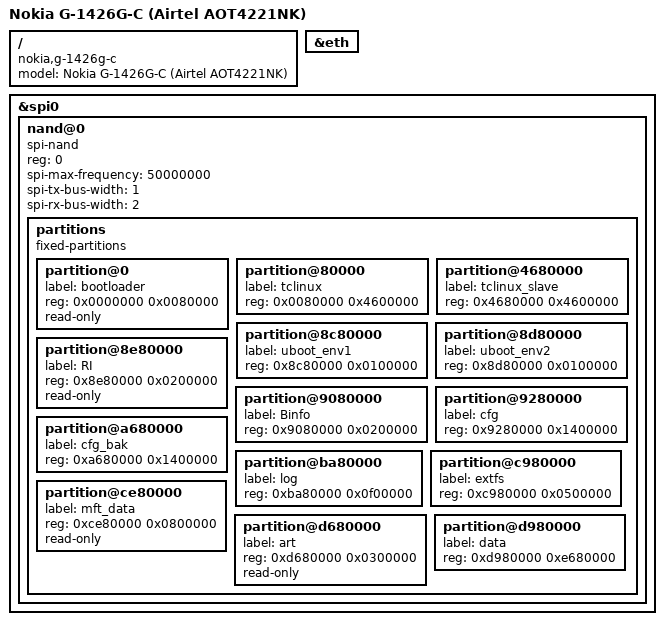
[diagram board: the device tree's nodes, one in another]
// SPDX-License-Identifier: (GPL-2.0-only OR BSD-2-Clause)
/dts-v1/;

#include "an7552.dtsi"

/ {
	model = "Nokia G-1426G-C (Airtel AOT4221NK)";
	compatible = "nokia,g-1426g-c", "airoha,an7552";
};

&eth {
	status = "okay";
};

&spi0 {
	status = "okay";

	nand@0 {
		compatible = "spi-nand";
		reg = <0>;
		spi-max-frequency = <50000000>;
		spi-tx-bus-width = <1>;
		spi-rx-bus-width = <2>;

		partitions {
			compatible = "fixed-partitions";
			#address-cells = <1>;
			#size-cells = <1>;

			partition@0 {
				label = "bootloader";
				reg = <0x0000000 0x0080000>;
				read-only;
			};

			partition@80000 {
				label = "tclinux";
				reg = <0x0080000 0x4600000>;
			};

			partition@4680000 {
				label = "tclinux_slave";
				reg = <0x4680000 0x4600000>;
			};

			partition@8c80000 {
				label = "uboot_env1";
				reg = <0x8c80000 0x0100000>;
			};

			partition@8d80000 {
				label = "uboot_env2";
				reg = <0x8d80000 0x0100000>;
			};

			partition@8e80000 {
				label = "RI";
				reg = <0x8e80000 0x0200000>;
				read-only;
			};

			partition@9080000 {
				label = "Binfo";
				reg = <0x9080000 0x0200000>;
			};

			partition@9280000 {
				label = "cfg";
				reg = <0x9280000 0x1400000>;
			};

			partition@a680000 {
				label = "cfg_bak";
				reg = <0xa680000 0x1400000>;
			};

			partition@ba80000 {
				label = "log";
				reg = <0xba80000 0x0f00000>;
			};

			partition@c980000 {
				label = "extfs";
				reg = <0xc980000 0x0500000>;
			};

			partition@ce80000 {
				label = "mft_data";
				reg = <0xce80000 0x0800000>;
				read-only;
			};

			partition@d680000 {
				label = "art";
				reg = <0xd680000 0x0300000>;
				read-only;
			};

			/*
			 * Ends at 0x1c000000; 0x1c000000..0x20000000 (64 MiB) is left
			 * unmapped to preserve the vendor U-Boot BMT pool.
			 */
			partition@d980000 {
				label = "data";
				reg = <0xd980000 0xe680000>;
			};
		};
	};
};
